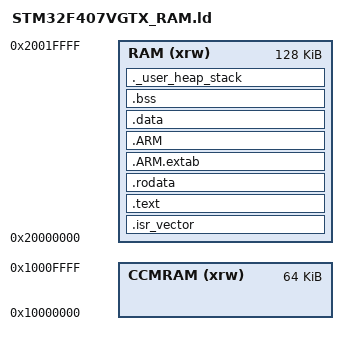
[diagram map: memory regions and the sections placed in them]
/*
******************************************************************************
**
**  File        : STM32F407VGTX_RAM.ld
**
**  Target      : STM32F407VGT6 (RAM Execution)
**
******************************************************************************
*/

/* Entry Point */
ENTRY(Reset_Handler)

/* Highest address of the user mode stack */
_estack = ORIGIN(RAM) + LENGTH(RAM);

_Min_Heap_Size = 0x200;
_Min_Stack_Size = 0x400;

MEMORY
{
  CCMRAM (xrw) : ORIGIN = 0x10000000, LENGTH = 64K
  RAM    (xrw) : ORIGIN = 0x20000000, LENGTH = 128K
}

SECTIONS
{
  .isr_vector :
  {
    . = ALIGN(4);
    KEEP(*(.isr_vector))
    . = ALIGN(4);
  } >RAM

  .text :
  {
    . = ALIGN(4);
    *(.text)
    *(.text*)
    *(.glue_7)
    *(.glue_7t)
    *(.eh_frame)

    KEEP (*(.init))
    KEEP (*(.fini))

    . = ALIGN(4);
    _etext = .;
  } >RAM

  .rodata :
  {
    . = ALIGN(4);
    *(.rodata)
    *(.rodata*)
    . = ALIGN(4);
  } >RAM

  .ARM.extab : {
    . = ALIGN(4);
    *(.ARM.extab* .gnu.linkonce.armextab.*)
    . = ALIGN(4);
  } >RAM

  .ARM : {
    . = ALIGN(4);
    __exidx_start = .;
    *(.ARM.exidx*)
    __exidx_end = .;
    . = ALIGN(4);
  } >RAM

  _sidata = .;

  .data :
  {
    . = ALIGN(4);
    _sdata = .;
    *(.data)
    *(.data*)
    . = ALIGN(4);
    _edata = .;
  } >RAM

  .bss :
  {
    . = ALIGN(4);
    _sbss = .;
    __bss_start__ = _sbss;
    *(.bss)
    *(.bss*)
    *(COMMON)
    . = ALIGN(4);
    _ebss = .;
    __bss_end__ = _ebss;
  } >RAM

  ._user_heap_stack :
  {
    . = ALIGN(8);
    PROVIDE ( end = . );
    PROVIDE ( _end = . );
    . = . + _Min_Heap_Size;
    . = . + _Min_Stack_Size;
    . = ALIGN(8);
  } >RAM

  /DISCARD/ :
  {
    libc.a ( * )
    libm.a ( * )
    libgcc.a ( * )
  }

  .ARM.attributes 0 : { *(.ARM.attributes) }
}
